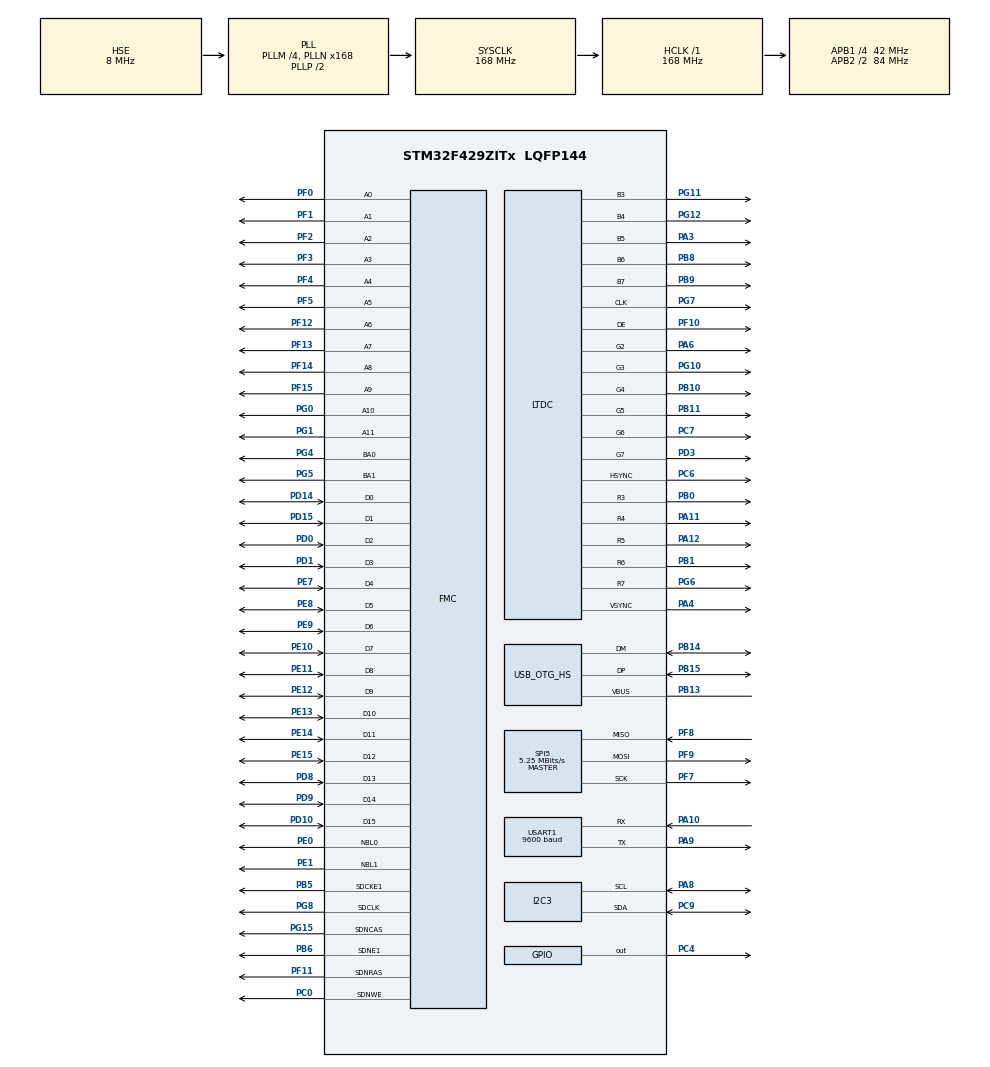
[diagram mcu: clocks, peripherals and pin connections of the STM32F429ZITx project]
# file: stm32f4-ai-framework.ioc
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DMA2D.ColorMode=DMA2D_OUTPUT_ARGB8888
DMA2D.InputColorModeForeground=DMA2D_INPUT_RGB888
DMA2D.Mode=DMA2D_M2M_PFC
FATFS._FS_RPATH=1
FATFS._USE_FIND=1
FATFS._USE_LFN=1
FMC.CASLatency1=FMC_SDRAM_CAS_LATENCY_3
FMC.ExitSelfRefreshDelay1=7
FMC.LoadToActiveDelay1=2
FMC.RCDDelay1=2
FMC.RPDelay1=2
FMC.RPDelay2=2
FMC.ReadPipeDelay1=FMC_SDRAM_RPIPE_DELAY_1
FMC.ReadPipeDelay2=FMC_SDRAM_RPIPE_DELAY_1
FMC.RowCycleDelay1=7
FMC.RowCycleDelay2=7
FMC.SDClockPeriod1=FMC_SDRAM_CLOCK_PERIOD_2
FMC.SDClockPeriod2=FMC_SDRAM_CLOCK_PERIOD_2
FMC.SelfRefreshTime1=4
FMC.WriteRecoveryTime1=3
LTDC.ActiveH=320
LTDC.ActiveW=240
LTDC.Alpha_L0=0
LTDC.BlendingFactor1_L0=LTDC_BLENDING_FACTOR1_CA
LTDC.BlendingFactor2_L0=LTDC_BLENDING_FACTOR2_CA
LTDC.FBStartAdress_L0=0xD0000000
LTDC.HBP=20
LTDC.HFP=10
LTDC.HSync=10
LTDC.ImageHeight_L0=320
LTDC.ImageWidth_L0=240
LTDC.Layers=0
LTDC.PixelFormat_L0=LTDC_PIXEL_FORMAT_ARGB8888
LTDC.VBP=2
LTDC.VFP=4
LTDC.VSync=2
LTDC.WindowX1_L0=240
LTDC.WindowY1_L0=320
LTDC.WindowY1_L1=0
Mcu.Family=STM32F4
Mcu.Name=STM32F429ZITx
Mcu.Package=LQFP144
NVIC.DMA2D_IRQn=true\:5\:0\:true\:false\:true\:true\:true\:true
NVIC.LTDC_IRQn=true\:5\:0\:true\:false\:true\:true\:true\:true
NVIC.OTG_HS_IRQn=true\:0\:0\:false\:false\:true\:true\:true\:true
NVIC.PriorityGroup=NVIC_PRIORITYGROUP_4
PA10.Mode=Asynchronous
PA10.Signal=USART1_RX
PA11.Mode=RGB565
PA11.Signal=LTDC_R4
PA12.Mode=RGB565
PA12.Signal=LTDC_R5
PA3.Mode=RGB565
PA3.Signal=LTDC_B5
PA4.Mode=RGB565
PA4.Signal=LTDC_VSYNC
PA6.Mode=RGB565
PA6.Signal=LTDC_G2
PA8.Mode=I2C
PA8.Signal=I2C3_SCL
PA9.Mode=Asynchronous
PA9.Signal=USART1_TX
PB0.Mode=RGB565
PB0.Signal=LTDC_R3
PB1.Mode=RGB565
PB1.Signal=LTDC_R6
PB10.Mode=RGB565
PB10.Signal=LTDC_G4
PB11.Mode=RGB565
PB11.Signal=LTDC_G5
PB13.Mode=Activate_VBUS_FS
PB13.Signal=USB_OTG_HS_VBUS
PB14.Mode=Host_FS
PB14.Signal=USB_OTG_HS_DM
PB15.Mode=Host_FS
PB15.Signal=USB_OTG_HS_DP
PB5.Mode=SdramChipSelect2_1
PB5.Signal=FMC_SDCKE1
PB6.Mode=SdramChipSelect2_1
PB6.Signal=FMC_SDNE1
PB8.Mode=RGB565
PB8.Signal=LTDC_B6
PB9.Mode=RGB565
PB9.Signal=LTDC_B7
PC0.Signal=FMC_SDNWE
PC4.Signal=GPIO_Output
PC6.Mode=RGB565
PC6.Signal=LTDC_HSYNC
PC7.Mode=RGB565
PC7.Signal=LTDC_G6
PC9.Mode=I2C
PC9.Signal=I2C3_SDA
PD0.Signal=FMC_D2_DA2
PD1.Signal=FMC_D3_DA3
PD10.Signal=FMC_D15_DA15
PD14.Signal=FMC_D0_DA0
PD15.Signal=FMC_D1_DA1
PD3.Mode=RGB565
PD3.Signal=LTDC_G7
PD8.Signal=FMC_D13_DA13
PD9.Signal=FMC_D14_DA14
PE0.Signal=FMC_NBL0
PE1.Signal=FMC_NBL1
PE10.Signal=FMC_D7_DA7
PE11.Signal=FMC_D8_DA8
PE12.Signal=FMC_D9_DA9
PE13.Signal=FMC_D10_DA10
PE14.Signal=FMC_D11_DA11
PE15.Signal=FMC_D12_DA12
PE7.Signal=FMC_D4_DA4
PE8.Signal=FMC_D5_DA5
PE9.Signal=FMC_D6_DA6
PF0.Signal=FMC_A0
PF1.Signal=FMC_A1
PF10.Mode=RGB565
PF10.Signal=LTDC_DE
PF11.Signal=FMC_SDNRAS
PF12.Signal=FMC_A6
PF13.Signal=FMC_A7
PF14.Signal=FMC_A8
PF15.Signal=FMC_A9
PF2.Signal=FMC_A2
PF3.Signal=FMC_A3
PF4.Signal=FMC_A4
PF5.Signal=FMC_A5
PF7.Mode=Full_Duplex_Master
PF7.Signal=SPI5_SCK
PF8.Mode=Full_Duplex_Master
PF8.Signal=SPI5_MISO
PF9.Mode=Full_Duplex_Master
PF9.Signal=SPI5_MOSI
PG0.Signal=FMC_A10
PG1.Signal=FMC_A11
PG10.Mode=RGB565
PG10.Signal=LTDC_G3
PG11.Mode=RGB565
PG11.Signal=LTDC_B3
PG12.Mode=RGB565
PG12.Signal=LTDC_B4
PG15.Signal=FMC_SDNCAS
PG4.Signal=FMC_A14_BA0
PG5.Signal=FMC_A15_BA1
PG6.Mode=RGB565
PG6.Signal=LTDC_R7
PG7.Mode=RGB565
PG7.Signal=LTDC_CLK
PG8.Signal=FMC_SDCLK
PH0/OSC_IN.Mode=HSE-External-Oscillator
PH0/OSC_IN.Signal=RCC_OSC_IN
PH1/OSC_OUT.Mode=HSE-External-Oscillator
PH1/OSC_OUT.Signal=RCC_OSC_OUT
ProjectManager.HeapSize=0x800
ProjectManager.StackSize=0x1000
ProjectManager.TargetToolchain=STM32CubeIDE
RCC.48MHZClocksFreq_Value=48000000
RCC.AHBFreq_Value=168000000
RCC.APB1CLKDivider=RCC_HCLK_DIV4
RCC.APB1Freq_Value=42000000
RCC.APB1TimFreq_Value=84000000
RCC.APB2CLKDivider=RCC_HCLK_DIV2
RCC.APB2Freq_Value=84000000
RCC.APB2TimFreq_Value=168000000
RCC.CortexFreq_Value=168000000
RCC.HCLKFreq_Value=168000000
RCC.HSE_VALUE=8000000
RCC.HSI_VALUE=16000000
RCC.LSE_VALUE=32768
RCC.PLLM=4
RCC.PLLN=168
RCC.PLLQ=7
RCC.PLLSAIDivR=RCC_PLLSAIDIVR_8
RCC.PLLSAIN=192
RCC.PLLSAIR=4
RCC.SYSCLKFreq_VALUE=168000000
RCC.SYSCLKSource=RCC_SYSCLKSOURCE_PLLCLK
RCC.VCOOutputFreq_Value=336000000
SH.FMC_A0.0=FMC_A0,12b-sda1
SH.FMC_A1.0=FMC_A1,12b-sda1
SH.FMC_A10.0=FMC_A10,12b-sda1
SH.FMC_A11.0=FMC_A11,12b-sda1
SH.FMC_A14_BA0.0=FMC_BA0,FourSdramBanks1
SH.FMC_A15_BA1.0=FMC_BA1,FourSdramBanks1
SH.FMC_A2.0=FMC_A2,12b-sda1
SH.FMC_A3.0=FMC_A3,12b-sda1
SH.FMC_A4.0=FMC_A4,12b-sda1
SH.FMC_A5.0=FMC_A5,12b-sda1
SH.FMC_A6.0=FMC_A6,12b-sda1
SH.FMC_A7.0=FMC_A7,12b-sda1
SH.FMC_A8.0=FMC_A8,12b-sda1
SH.FMC_A9.0=FMC_A9,12b-sda1
SH.FMC_D0_DA0.0=FMC_D0,sd-16b-d1
SH.FMC_D10_DA10.0=FMC_D10,sd-16b-d1
SH.FMC_D11_DA11.0=FMC_D11,sd-16b-d1
SH.FMC_D12_DA12.0=FMC_D12,sd-16b-d1
SH.FMC_D13_DA13.0=FMC_D13,sd-16b-d1
SH.FMC_D14_DA14.0=FMC_D14,sd-16b-d1
SH.FMC_D15_DA15.0=FMC_D15,sd-16b-d1
SH.FMC_D1_DA1.0=FMC_D1,sd-16b-d1
SH.FMC_D2_DA2.0=FMC_D2,sd-16b-d1
SH.FMC_D3_DA3.0=FMC_D3,sd-16b-d1
SH.FMC_D4_DA4.0=FMC_D4,sd-16b-d1
SH.FMC_D5_DA5.0=FMC_D5,sd-16b-d1
SH.FMC_D6_DA6.0=FMC_D6,sd-16b-d1
SH.FMC_D7_DA7.0=FMC_D7,sd-16b-d1
SH.FMC_D8_DA8.0=FMC_D8,sd-16b-d1
SH.FMC_D9_DA9.0=FMC_D9,sd-16b-d1
SH.FMC_NBL0.0=FMC_NBL0,Sd2ByteEnable1
SH.FMC_NBL1.0=FMC_NBL1,Sd2ByteEnable1
SH.FMC_SDCLK.0=FMC_SDCLK,12b-sda1
SH.FMC_SDNCAS.0=FMC_SDNCAS,12b-sda1
SH.FMC_SDNRAS.0=FMC_SDNRAS,12b-sda1
SH.FMC_SDNWE.0=FMC_SDNWE,12b-sda1
SPI5.BaudRatePrescaler=SPI_BAUDRATEPRESCALER_16
SPI5.CalculateBaudRate=5.25 MBits/s
SPI5.Direction=SPI_DIRECTION_2LINES
SPI5.Mode=SPI_MODE_MASTER
SPI5.VirtualType=VM_MASTER
STMicroelectronics.X-CUBE-AI.7.1.0.ActivationBufferSizeList=794703
STMicroelectronics.X-CUBE-AI.7.1.0.ActivationBuffers=(ai_handle) 0xD0400000
STMicroelectronics.X-CUBE-AI.7.1.0.ActivationPragmas=AI_EXTERNAL_SDRAM
STMicroelectronics.X-CUBE-AI.7.1.0.ApplicationCcDeviceJjApplication=ApplicationTemplate
STMicroelectronics.X-CUBE-AI.7.1.0.ExternalRamActivationBufferMaxSize=794703
STMicroelectronics.X-CUBE-AI.7.1.0.ExternalRamActivationBufferStartAddr=0xD0400000
STMicroelectronics.X-CUBE-AI.7.1.0.HeapSize=0x800
STMicroelectronics.X-CUBE-AI.7.1.0.LatestDirectoryUsed-c69e1e71af59e9284d8c9ebcd018e26e2616c1a4c7abbe01e2eb5ee08dc400ba=/Users/sasageyo/STM32CubeIDE/workspace_1.10.1/stm32f4-ai-framework/Model
STMicroelectronics.X-CUBE-AI.7.1.0.MaximumNumberOfInputLayer=1
STMicroelectronics.X-CUBE-AI.7.1.0.MaximumNumberOfOutputLayer=1
STMicroelectronics.X-CUBE-AI.7.1.0.MaximumSizeOfInputLayer=AI_NETWORK_IN_1_SIZE_BYTES
STMicroelectronics.X-CUBE-AI.7.1.0.MaximumSizeOfOutputLayer=AI_NETWORK_OUT_1_SIZE_BYTES
STMicroelectronics.X-CUBE-AI.7.1.0.ModelActualCompression-c69e1e71af59e9284d8c9ebcd018e26e2616c1a4c7abbe01e2eb5ee08dc400ba=0.0
STMicroelectronics.X-CUBE-AI.7.1.0.ModelCompression-c69e1e71af59e9284d8c9ebcd018e26e2616c1a4c7abbe01e2eb5ee08dc400ba=1
STMicroelectronics.X-CUBE-AI.7.1.0.ModelFlashOccupation-c69e1e71af59e9284d8c9ebcd018e26e2616c1a4c7abbe01e2eb5ee08dc400ba=662016
STMicroelectronics.X-CUBE-AI.7.1.0.ModelHashList=c69e1e71af59e9284d8c9ebcd018e26e2616c1a4c7abbe01e2eb5ee08dc400ba
STMicroelectronics.X-CUBE-AI.7.1.0.ModelKind-c69e1e71af59e9284d8c9ebcd018e26e2616c1a4c7abbe01e2eb5ee08dc400ba=TFLITE
STMicroelectronics.X-CUBE-AI.7.1.0.ModelMacc-c69e1e71af59e9284d8c9ebcd018e26e2616c1a4c7abbe01e2eb5ee08dc400ba=58587404
STMicroelectronics.X-CUBE-AI.7.1.0.ModelName-c69e1e71af59e9284d8c9ebcd018e26e2616c1a4c7abbe01e2eb5ee08dc400ba=network
STMicroelectronics.X-CUBE-AI.7.1.0.ModelNameList=network
STMicroelectronics.X-CUBE-AI.7.1.0.ModelRamOccupation-c69e1e71af59e9284d8c9ebcd018e26e2616c1a4c7abbe01e2eb5ee08dc400ba=794703
STMicroelectronics.X-CUBE-AI.7.1.0.ModelStructureFile-c69e1e71af59e9284d8c9ebcd018e26e2616c1a4c7abbe01e2eb5ee08dc400ba=Model/model.tflite
STMicroelectronics.X-CUBE-AI.7.1.0.ModelType-c69e1e71af59e9284d8c9ebcd018e26e2616c1a4c7abbe01e2eb5ee08dc400ba=STM32Cube.AI runtime
STMicroelectronics.X-CUBE-AI.7.1.0.ReadyForCodeGeneration=true
STMicroelectronics.X-CUBE-AI.7.1.0.StackSize=0x1000
STMicroelectronics.X-CUBE-AI.7.1.0.WorkingBufferStartAddr-c69e1e71af59e9284d8c9ebcd018e26e2616c1a4c7abbe01e2eb5ee08dc400ba=0xD0400000
STMicroelectronics.X-CUBE-AI.7.1.0.WorkingBufferStartAddrList=0xD0400000
STMicroelectronics.X-CUBE-AI.7.1.0.XAaCUBEAaAICcArtificialOoIntelligenceJjCore=true
STMicroelectronics.X-CUBE-AI.7.1.0.actBufferSize-c69e1e71af59e9284d8c9ebcd018e26e2616c1a4c7abbe01e2eb5ee08dc400ba=0
STMicroelectronics.X-CUBE-AI.7.1.0.bspIncludes=stm32f429i_discovery_sdram.h,stm32f429i_discovery.h
STMicroelectronics.X-CUBE-AI.7.1.0.copyWeightToRam-c69e1e71af59e9284d8c9ebcd018e26e2616c1a4c7abbe01e2eb5ee08dc400ba=false
STMicroelectronics.X-CUBE-AI.7.1.0.customLayerConfigEnabled-c69e1e71af59e9284d8c9ebcd018e26e2616c1a4c7abbe01e2eb5ee08dc400ba=false
STMicroelectronics.X-CUBE-AI.7.1.0.extRamDriver-c69e1e71af59e9284d8c9ebcd018e26e2616c1a4c7abbe01e2eb5ee08dc400ba=External SDRAM
STMicroelectronics.X-CUBE-AI.7.1.0.extRamStartAddr-c69e1e71af59e9284d8c9ebcd018e26e2616c1a4c7abbe01e2eb5ee08dc400ba=0xD0000000
STMicroelectronics.X-CUBE-AI.7.1.0.initFunctions=BSP_SDRAM_Init();
STMicroelectronics.X-CUBE-AI.7.1.0.memoryPool0driver-c69e1e71af59e9284d8c9ebcd018e26e2616c1a4c7abbe01e2eb5ee08dc400ba=External SDRAM
STMicroelectronics.X-CUBE-AI.7.1.0.memoryPool0id-c69e1e71af59e9284d8c9ebcd018e26e2616c1a4c7abbe01e2eb5ee08dc400ba=0
STMicroelectronics.X-CUBE-AI.7.1.0.memoryPool0max-c69e1e71af59e9284d8c9ebcd018e26e2616c1a4c7abbe01e2eb5ee08dc400ba=8192
STMicroelectronics.X-CUBE-AI.7.1.0.memoryPool0name-c69e1e71af59e9284d8c9ebcd018e26e2616c1a4c7abbe01e2eb5ee08dc400ba=pool
STMicroelectronics.X-CUBE-AI.7.1.0.memoryPool0size-c69e1e71af59e9284d8c9ebcd018e26e2616c1a4c7abbe01e2eb5ee08dc400ba=4096
STMicroelectronics.X-CUBE-AI.7.1.0.memoryPool0start-c69e1e71af59e9284d8c9ebcd018e26e2616c1a4c7abbe01e2eb5ee08dc400ba=0xD0400000
STMicroelectronics.X-CUBE-AI.7.1.0.memoryPool0used-c69e1e71af59e9284d8c9ebcd018e26e2616c1a4c7abbe01e2eb5ee08dc400ba=0.0
STMicroelectronics.X-CUBE-AI.7.1.0.useActivationBuffer-c69e1e71af59e9284d8c9ebcd018e26e2616c1a4c7abbe01e2eb5ee08dc400ba=true
STMicroelectronics.X-CUBE-AI.7.1.0.useExternalRam-c69e1e71af59e9284d8c9ebcd018e26e2616c1a4c7abbe01e2eb5ee08dc400ba=true
USART1.BaudRate=9600
USART1.VirtualMode=VM_ASYNC
USB_HOST.BSP.number=1
USB_HOST.USBH_HandleTypeDef-MSC_HS=hUsbHostHS
USB_HOST.VirtualModeHS=Msc
USB_HOST0.BSP.STBoard=false
USB_HOST0.BSP.api=Unknown
USB_HOST0.BSP.instance=PC4
USB_HOST0.BSP.ip=GPIO
USB_HOST0.BSP.mode=Output
USB_HOST0.BSP.name=Drive_VBUS_HS
USB_HOST0.BSP.solution=PC4
USB_OTG_HS.VirtualMode-Host_FS=Host_FS
VP_CRC_VS_CRC.Mode=CRC_Activate
VP_DMA2D_VS_DMA2D.Mode=DMA2D_Activate
VP_FATFS_VS_USB.Mode=USB
VP_LIBJPEG_VS_JPEGLIB.Mode=Enabled
VP_RTC_VS_RTC_Activate.Mode=RTC_Enabled
VP_STMicroelectronics.X-CUBE-AI_VS_ArtificialOoIntelligenceJjXAaCUBEAaAI_7.1.0.Mode=ArtificialOoIntelligenceJjXAaCUBEAaAI
VP_STMicroelectronics.X-CUBE-AI_VS_DeviceJjApplication_7.1.0.Mode=DeviceJjApplication
VP_USB_HOST_VS_USB_HOST_MSC_HS.Mode=MSC_HS
board=STM32F429I-DISC1

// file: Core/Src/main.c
/* USER CODE BEGIN Header */
/**
 ******************************************************************************
 * @file	: main.c
 * @brief	: Main program body
 * @authors	: Conti Edoardo, Federici Lorenzo, Melnic Andrian
 * @course	: Sistemi Operativi Dedicati @ UNIVPM (2021/2022)
 ******************************************************************************
 * @attention
 *
 * Copyright (c) 2022 STMicroelectronics.
 * All rights reserved.
 *
 * This software is licensed under terms that can be found in the LICENSE file
 * in the root directory of this software component.
 * If no LICENSE file comes with this software, it is provided AS-IS.
 *
 ******************************************************************************
 */
/* USER CODE END Header */
#include "main.h"
#include "fatfs.h"
#include "libjpeg.h"
#include "app_x-cube-ai.h"
#include "usb_host.h"

/* USER CODE BEGIN Includes */
#include "utils.h"
/* USER CODE END Includes */

CRC_HandleTypeDef hcrc;

DMA2D_HandleTypeDef hdma2d;

I2C_HandleTypeDef hi2c3;

LTDC_HandleTypeDef hltdc;

RTC_HandleTypeDef hrtc;

SPI_HandleTypeDef hspi5;

UART_HandleTypeDef huart1;

SDRAM_HandleTypeDef hsdram1;

/* USER CODE BEGIN PV */
/*
 * Variables declared in "utils.h" are defined here
 * source: https://stackoverflow.com/q/1433204
 */
uint8_t *scanline_buffer;
uint8_t *image_buffer;
__attribute__((section(".extram"))) uint8_t image_buffer_resized[IMGBUFFERSIZE];

// counter increased every time an image is decoded and processed
int imgs_processed = 0;
/* USER CODE END PV */

void SystemClock_Config(void);
static void MX_GPIO_Init(void);
static void MX_DMA2D_Init(void);
static void MX_FMC_Init(void);
static void MX_I2C3_Init(void);
static void MX_LTDC_Init(void);
static void MX_SPI5_Init(void);
static void MX_USART1_UART_Init(void);
static void MX_CRC_Init(void);
static void MX_RTC_Init(void);
void MX_USB_HOST_Process(void);

/* USER CODE BEGIN PFP */
static void LCD_Config(void);
void DMA2D_BufferImage2LCD(uint32_t data, uint32_t x, uint32_t y, uint32_t width, uint32_t height);
void Scan_JPGs(void);
/* USER CODE END PFP */

int main(void)
{

  /* MCU Configuration--------------------------------------------------------*/

  /* Reset of all peripherals, Initializes the Flash interface and the Systick. */
  HAL_Init();

  /* Configure the system clock */
  SystemClock_Config();

  /* Initialize all configured peripherals */
  MX_GPIO_Init();
  MX_DMA2D_Init();
  MX_FMC_Init();
  MX_I2C3_Init();
  MX_LTDC_Init();
  MX_SPI5_Init();
  MX_USART1_UART_Init();
  MX_CRC_Init();
  MX_FATFS_Init();
  MX_LIBJPEG_Init();
  MX_USB_HOST_Init();
  MX_RTC_Init();
  MX_X_CUBE_AI_Init();
  /* USER CODE BEGIN 2 */
	#if VERBOSE_LEVEL == 2
		printf("[%s:%d] configuring the LCD... \r\n", __FILE__, __LINE__);
	#endif

	// configuring the LCD...
	LCD_Config();

	// now i can write on it
	BSP_LCD_DisplayStringAt(0, LINE(1), (uint8_t*)"STM32 AI Framework", CENTER_MODE);
	BSP_LCD_DisplayStringAt(0, LINE(2), (uint8_t*)"SOD@UNIVPM 2022", CENTER_MODE);
	BSP_LCD_DisplayStringAt(0, LINE(4), (uint8_t*)"TEACHABLE MACHINE", CENTER_MODE);

	HAL_Delay(2000);
	BSP_LCD_Clear(LCD_COLOR_BLACK);
  /* USER CODE END 2 */

  /* Infinite loop */
	while (1)
	{
    MX_USB_HOST_Process();

 	// MX_X_CUBE_AI_Process();
    /* USER CODE BEGIN 3 */
		switch(Appli_state){
		case APPLICATION_READY:
			#if VERBOSE_LEVEL == 2
				printf("[%s:%d] scan for JPGs on USB host...\r\n", __FILE__, __LINE__);
			#endif
			// start to read images and process them
			Scan_JPGs();

			// quit when all the images have been read
			Appli_state = APPLICATION_IDLE;
			break;
		case APPLICATION_IDLE:
			// printf("IDLE\r\n");
		default:
			break;
		}

	}
  /* USER CODE END 3 */
}

void SystemClock_Config(void)
{
  RCC_OscInitTypeDef RCC_OscInitStruct = {0};
  RCC_ClkInitTypeDef RCC_ClkInitStruct = {0};

  /** Configure the main internal regulator output voltage
  */
  __HAL_RCC_PWR_CLK_ENABLE();
  __HAL_PWR_VOLTAGESCALING_CONFIG(PWR_REGULATOR_VOLTAGE_SCALE1);

  /** Initializes the RCC Oscillators according to the specified parameters
  * in the RCC_OscInitTypeDef structure.
  */
  RCC_OscInitStruct.OscillatorType = RCC_OSCILLATORTYPE_LSI|RCC_OSCILLATORTYPE_HSE;
  RCC_OscInitStruct.HSEState = RCC_HSE_ON;
  RCC_OscInitStruct.LSIState = RCC_LSI_ON;
  RCC_OscInitStruct.PLL.PLLState = RCC_PLL_ON;
  RCC_OscInitStruct.PLL.PLLSource = RCC_PLLSOURCE_HSE;
  RCC_OscInitStruct.PLL.PLLM = 4;
  RCC_OscInitStruct.PLL.PLLN = 168;
  RCC_OscInitStruct.PLL.PLLP = RCC_PLLP_DIV2;
  RCC_OscInitStruct.PLL.PLLQ = 7;
  if (HAL_RCC_OscConfig(&RCC_OscInitStruct) != HAL_OK)
  {
    Error_Handler();
  }

  /** Initializes the CPU, AHB and APB buses clocks
  */
  RCC_ClkInitStruct.ClockType = RCC_CLOCKTYPE_HCLK|RCC_CLOCKTYPE_SYSCLK
                              |RCC_CLOCKTYPE_PCLK1|RCC_CLOCKTYPE_PCLK2;
  RCC_ClkInitStruct.SYSCLKSource = RCC_SYSCLKSOURCE_PLLCLK;
  RCC_ClkInitStruct.AHBCLKDivider = RCC_SYSCLK_DIV1;
  RCC_ClkInitStruct.APB1CLKDivider = RCC_HCLK_DIV4;
  RCC_ClkInitStruct.APB2CLKDivider = RCC_HCLK_DIV2;

  if (HAL_RCC_ClockConfig(&RCC_ClkInitStruct, FLASH_LATENCY_5) != HAL_OK)
  {
    Error_Handler();
  }
}

static void MX_CRC_Init(void)
{

  hcrc.Instance = CRC;
  if (HAL_CRC_Init(&hcrc) != HAL_OK)
  {
    Error_Handler();
  }

}

static void MX_DMA2D_Init(void)
{

  /* USER CODE BEGIN DMA2D_Init 0 */
	//
  /* USER CODE END DMA2D_Init 0 */

  /* USER CODE BEGIN DMA2D_Init 1 */
	//
  /* USER CODE END DMA2D_Init 1 */
  hdma2d.Instance = DMA2D;
  hdma2d.Init.Mode = DMA2D_M2M_PFC;
  hdma2d.Init.ColorMode = DMA2D_OUTPUT_ARGB8888;
  hdma2d.Init.OutputOffset = 0;
  hdma2d.LayerCfg[1].InputOffset = 0;
  hdma2d.LayerCfg[1].InputColorMode = DMA2D_INPUT_RGB888;
  hdma2d.LayerCfg[1].AlphaMode = DMA2D_NO_MODIF_ALPHA;
  hdma2d.LayerCfg[1].InputAlpha = 0;
  if (HAL_DMA2D_Init(&hdma2d) != HAL_OK)
  {
    Error_Handler();
  }
  if (HAL_DMA2D_ConfigLayer(&hdma2d, 1) != HAL_OK)
  {
    Error_Handler();
  }
  /* USER CODE BEGIN DMA2D_Init 2 */
	//
  /* USER CODE END DMA2D_Init 2 */

}

static void MX_I2C3_Init(void)
{

  hi2c3.Instance = I2C3;
  hi2c3.Init.ClockSpeed = 100000;
  hi2c3.Init.DutyCycle = I2C_DUTYCYCLE_2;
  hi2c3.Init.OwnAddress1 = 0;
  hi2c3.Init.AddressingMode = I2C_ADDRESSINGMODE_7BIT;
  hi2c3.Init.DualAddressMode = I2C_DUALADDRESS_DISABLE;
  hi2c3.Init.OwnAddress2 = 0;
  hi2c3.Init.GeneralCallMode = I2C_GENERALCALL_DISABLE;
  hi2c3.Init.NoStretchMode = I2C_NOSTRETCH_DISABLE;
  if (HAL_I2C_Init(&hi2c3) != HAL_OK)
  {
    Error_Handler();
  }

  /** Configure Analogue filter
  */
  if (HAL_I2CEx_ConfigAnalogFilter(&hi2c3, I2C_ANALOGFILTER_ENABLE) != HAL_OK)
  {
    Error_Handler();
  }

  /** Configure Digital filter
  */
  if (HAL_I2CEx_ConfigDigitalFilter(&hi2c3, 0) != HAL_OK)
  {
    Error_Handler();
  }

}

static void MX_LTDC_Init(void)
{

  /* USER CODE BEGIN LTDC_Init 0 */
	//
  /* USER CODE END LTDC_Init 0 */

  LTDC_LayerCfgTypeDef pLayerCfg = {0};

  /* USER CODE BEGIN LTDC_Init 1 */
	//
  /* USER CODE END LTDC_Init 1 */
  hltdc.Instance = LTDC;
  hltdc.Init.HSPolarity = LTDC_HSPOLARITY_AL;
  hltdc.Init.VSPolarity = LTDC_VSPOLARITY_AL;
  hltdc.Init.DEPolarity = LTDC_DEPOLARITY_AL;
  hltdc.Init.PCPolarity = LTDC_PCPOLARITY_IPC;
  hltdc.Init.HorizontalSync = 9;
  hltdc.Init.VerticalSync = 1;
  hltdc.Init.AccumulatedHBP = 29;
  hltdc.Init.AccumulatedVBP = 3;
  hltdc.Init.AccumulatedActiveW = 269;
  hltdc.Init.AccumulatedActiveH = 323;
  hltdc.Init.TotalWidth = 279;
  hltdc.Init.TotalHeigh = 327;
  hltdc.Init.Backcolor.Blue = 0;
  hltdc.Init.Backcolor.Green = 0;
  hltdc.Init.Backcolor.Red = 0;
  if (HAL_LTDC_Init(&hltdc) != HAL_OK)
  {
    Error_Handler();
  }
  pLayerCfg.WindowX0 = 0;
  pLayerCfg.WindowX1 = 240;
  pLayerCfg.WindowY0 = 0;
  pLayerCfg.WindowY1 = 320;
  pLayerCfg.PixelFormat = LTDC_PIXEL_FORMAT_ARGB8888;
  pLayerCfg.Alpha = 0;
  pLayerCfg.Alpha0 = 0;
  pLayerCfg.BlendingFactor1 = LTDC_BLENDING_FACTOR1_CA;
  pLayerCfg.BlendingFactor2 = LTDC_BLENDING_FACTOR2_CA;
  pLayerCfg.FBStartAdress = 0xD0000000;
  pLayerCfg.ImageWidth = 240;
  pLayerCfg.ImageHeight = 320;
  pLayerCfg.Backcolor.Blue = 0;
  pLayerCfg.Backcolor.Green = 0;
  pLayerCfg.Backcolor.Red = 0;
  if (HAL_LTDC_ConfigLayer(&hltdc, &pLayerCfg, 0) != HAL_OK)
  {
    Error_Handler();
  }
  /* USER CODE BEGIN LTDC_Init 2 */
	//
  /* USER CODE END LTDC_Init 2 */

}

static void MX_RTC_Init(void)
{

  /** Initialize RTC Only
  */
  hrtc.Instance = RTC;
  hrtc.Init.HourFormat = RTC_HOURFORMAT_24;
  hrtc.Init.AsynchPrediv = 127;
  hrtc.Init.SynchPrediv = 255;
  hrtc.Init.OutPut = RTC_OUTPUT_DISABLE;
  hrtc.Init.OutPutPolarity = RTC_OUTPUT_POLARITY_HIGH;
  hrtc.Init.OutPutType = RTC_OUTPUT_TYPE_OPENDRAIN;
  if (HAL_RTC_Init(&hrtc) != HAL_OK)
  {
    Error_Handler();
  }

}

static void MX_SPI5_Init(void)
{

  /* SPI5 parameter configuration*/
  hspi5.Instance = SPI5;
  hspi5.Init.Mode = SPI_MODE_MASTER;
  hspi5.Init.Direction = SPI_DIRECTION_2LINES;
  hspi5.Init.DataSize = SPI_DATASIZE_8BIT;
  hspi5.Init.CLKPolarity = SPI_POLARITY_LOW;
  hspi5.Init.CLKPhase = SPI_PHASE_1EDGE;
  hspi5.Init.NSS = SPI_NSS_SOFT;
  hspi5.Init.BaudRatePrescaler = SPI_BAUDRATEPRESCALER_16;
  hspi5.Init.FirstBit = SPI_FIRSTBIT_MSB;
  hspi5.Init.TIMode = SPI_TIMODE_DISABLE;
  hspi5.Init.CRCCalculation = SPI_CRCCALCULATION_DISABLE;
  hspi5.Init.CRCPolynomial = 10;
  if (HAL_SPI_Init(&hspi5) != HAL_OK)
  {
    Error_Handler();
  }

}

static void MX_USART1_UART_Init(void)
{

  huart1.Instance = USART1;
  huart1.Init.BaudRate = 9600;
  huart1.Init.WordLength = UART_WORDLENGTH_8B;
  huart1.Init.StopBits = UART_STOPBITS_1;
  huart1.Init.Parity = UART_PARITY_NONE;
  huart1.Init.Mode = UART_MODE_TX_RX;
  huart1.Init.HwFlowCtl = UART_HWCONTROL_NONE;
  huart1.Init.OverSampling = UART_OVERSAMPLING_16;
  if (HAL_UART_Init(&huart1) != HAL_OK)
  {
    Error_Handler();
  }

}

/* FMC initialization function */
static void MX_FMC_Init(void)
{

  /* USER CODE BEGIN FMC_Init 0 */
	//
  /* USER CODE END FMC_Init 0 */

  FMC_SDRAM_TimingTypeDef SdramTiming = {0};

  /* USER CODE BEGIN FMC_Init 1 */
	//
  /* USER CODE END FMC_Init 1 */

  /** Perform the SDRAM1 memory initialization sequence
  */
  hsdram1.Instance = FMC_SDRAM_DEVICE;
  /* hsdram1.Init */
  hsdram1.Init.SDBank = FMC_SDRAM_BANK2;
  hsdram1.Init.ColumnBitsNumber = FMC_SDRAM_COLUMN_BITS_NUM_8;
  hsdram1.Init.RowBitsNumber = FMC_SDRAM_ROW_BITS_NUM_12;
  hsdram1.Init.MemoryDataWidth = FMC_SDRAM_MEM_BUS_WIDTH_16;
  hsdram1.Init.InternalBankNumber = FMC_SDRAM_INTERN_BANKS_NUM_4;
  hsdram1.Init.CASLatency = FMC_SDRAM_CAS_LATENCY_3;
  hsdram1.Init.WriteProtection = FMC_SDRAM_WRITE_PROTECTION_DISABLE;
  hsdram1.Init.SDClockPeriod = FMC_SDRAM_CLOCK_PERIOD_2;
  hsdram1.Init.ReadBurst = FMC_SDRAM_RBURST_DISABLE;
  hsdram1.Init.ReadPipeDelay = FMC_SDRAM_RPIPE_DELAY_1;
  /* SdramTiming */
  SdramTiming.LoadToActiveDelay = 2;
  SdramTiming.ExitSelfRefreshDelay = 7;
  SdramTiming.SelfRefreshTime = 4;
  SdramTiming.RowCycleDelay = 7;
  SdramTiming.WriteRecoveryTime = 3;
  SdramTiming.RPDelay = 2;
  SdramTiming.RCDDelay = 2;

  if (HAL_SDRAM_Init(&hsdram1, &SdramTiming) != HAL_OK)
  {
    Error_Handler( );
  }

}

static void MX_GPIO_Init(void)
{
  GPIO_InitTypeDef GPIO_InitStruct = {0};

  /* GPIO Ports Clock Enable */
  __HAL_RCC_GPIOF_CLK_ENABLE();
  __HAL_RCC_GPIOH_CLK_ENABLE();
  __HAL_RCC_GPIOC_CLK_ENABLE();
  __HAL_RCC_GPIOA_CLK_ENABLE();
  __HAL_RCC_GPIOB_CLK_ENABLE();
  __HAL_RCC_GPIOG_CLK_ENABLE();
  __HAL_RCC_GPIOE_CLK_ENABLE();
  __HAL_RCC_GPIOD_CLK_ENABLE();

  /*Configure GPIO pin Output Level */
  HAL_GPIO_WritePin(GPIOC, GPIO_PIN_4, GPIO_PIN_RESET);

  /*Configure GPIO pin : PC4 */
  GPIO_InitStruct.Pin = GPIO_PIN_4;
  GPIO_InitStruct.Mode = GPIO_MODE_OUTPUT_PP;
  GPIO_InitStruct.Pull = GPIO_NOPULL;
  GPIO_InitStruct.Speed = GPIO_SPEED_FREQ_LOW;
  HAL_GPIO_Init(GPIOC, &GPIO_InitStruct);

}

/* USER CODE BEGIN 4 */
int _write(int file, char *ptr, int len){
	HAL_UART_Transmit(&huart1,(uint8_t*)ptr,len,1000);

	return len;
}

static void LCD_Config(void)
{
	/* Initialize the LCD */
	BSP_LCD_Init();

	/* Background Layer Initialization */
	BSP_LCD_LayerDefaultInit(0, LCD_BUFFER);

	/* Set Foreground Layer */
	BSP_LCD_SelectLayer(0);

	/* Enable the LCD */
	BSP_LCD_DisplayOn();

	/* Clear the LCD Background layer */
	BSP_LCD_SetTransparency(0,255);
	BSP_LCD_Clear(LCD_COLOR_BLACK);
	BSP_LCD_SetFont(&Font16);
	BSP_LCD_SetTextColor(LCD_COLOR_WHITE);
	BSP_LCD_SetBackColor(LCD_COLOR_BLACK);
}

void DMA2D_BufferImage2LCD(uint32_t data, uint32_t x, uint32_t y, uint32_t width, uint32_t height)
{
	/*
	 * ensure to have configured the DMA2D with this settings
	 * - DMA2D_M2M_PFC : pixel format conversion
	 * the image buffer is stored as RGB888 (= 24bit, uint8_t for each channel)
	 * but the display is configured as ARGB8888 (= 32bit, uint32_t for each pixel)
	 * - MA2D_M2M : if InputColorMode == ColorMode (ARGB8888) but a previous conversion is required
	 * it consists of converting the image buffer to a ARGB32Buffer to store the image in 32bit
	 */

	hdma2d.Init.OutputOffset = BSP_LCD_GetXSize() - width;

	HAL_DMA2D_Init(&hdma2d);
	HAL_DMA2D_ConfigLayer(&hdma2d, 1);
	HAL_DMA2D_Start(&hdma2d, data, LCD_BUFFER + (x + y * BSP_LCD_GetXSize()) * 4, width, height);
	HAL_DMA2D_PollForTransfer(&hdma2d, 10);
}

void Scan_JPGs(void){
	// needed for manage the USB host's file system
	DIR dir;
	FILINFO fno;
	FRESULT res;
	int status;

	#if VERBOSE_LEVEL == 2
		printf("[%s:%d] searching images in %s ... \r\n", __FILE__, __LINE__, PATH_TO_JPEGS);
	#endif

	if (f_chdir(PATH_TO_JPEGS) == FR_OK){
		// looking for images .jpg and .jpeg format
		res = f_findfirst(&dir, &fno, "", "*.j*g");

		while((res == FR_OK) && (fno.fname[0])){
			printf("############### IMAGE N.%d ############### \r\n", ++imgs_processed);

			#if VERBOSE_LEVEL == 2
				printf("[%s:%d] decoding image %s \r\n", __FILE__, __LINE__, fno.fname);
			#elif VERBOSE_LEVEL == 1 || VERBOSE_LEVEL == 0
				printf("decoding image %s \r\n", fno.fname);
			#endif
			// decode, resize and store the image into the dedicated buffer
			status = ProcessJPG((uint8_t*)fno.fname);

			if(status) {
				/*
				 * print the resized image to the LCD using the Chrom-ART accelerator
				 * which offers hardware acceleration for STM32 graphical operations.
				 *
				 * other methods to draw the image buffer into the LCD:
				 * 1 -> convert the buffer to ARGB8888 format (32bit) in order to avoid the DMA2D_M2M_PFC
				 * 2 -> get a (uint8_t *) buffer compatible with the input format of the neural network
				 * 		it can also be done by casting the array (uint8_t *)image_buffer
				 */
				DMA2D_BufferImage2LCD(
					(uint32_t)image_buffer_resized,
					(BSP_LCD_GetXSize() - IMAGE_WIDTH) / 2,
					(BSP_LCD_GetXSize() - IMAGE_HEIGHT) / 2,
					IMAGE_WIDTH,
					IMAGE_HEIGHT
				);

				// AI process
				MX_X_CUBE_AI_Process();

				// wait 4s to read the neural network results
				HAL_Delay(1000);

				// clear the last AI results (todo: indices hard-coded)
				// for (int k = 10; k < 17; k++) BSP_LCD_ClearStringLine(k);
				BSP_LCD_Clear(LCD_COLOR_BLACK);
			}

			// search next image is exist
			res = f_findnext(&dir, &fno);
		}

		f_closedir(&dir);

		BSP_LCD_Clear(LCD_COLOR_BLACK);
		BSP_LCD_DisplayStringAt(0, LINE(1), (uint8_t*)"STM32 AI Framework", CENTER_MODE);
		BSP_LCD_DisplayStringAt(0, LINE(2), (uint8_t*)"SOD@UNIVPM 2022", CENTER_MODE);
		BSP_LCD_DisplayStringAt(0, LINE(4), (uint8_t*)"Program terminated", CENTER_MODE);

		printf("################   END   ################ \r\n");
	}
}
/* USER CODE END 4 */

void Error_Handler(void)
{
	__disable_irq();
	while (1)
	{
	}
}
